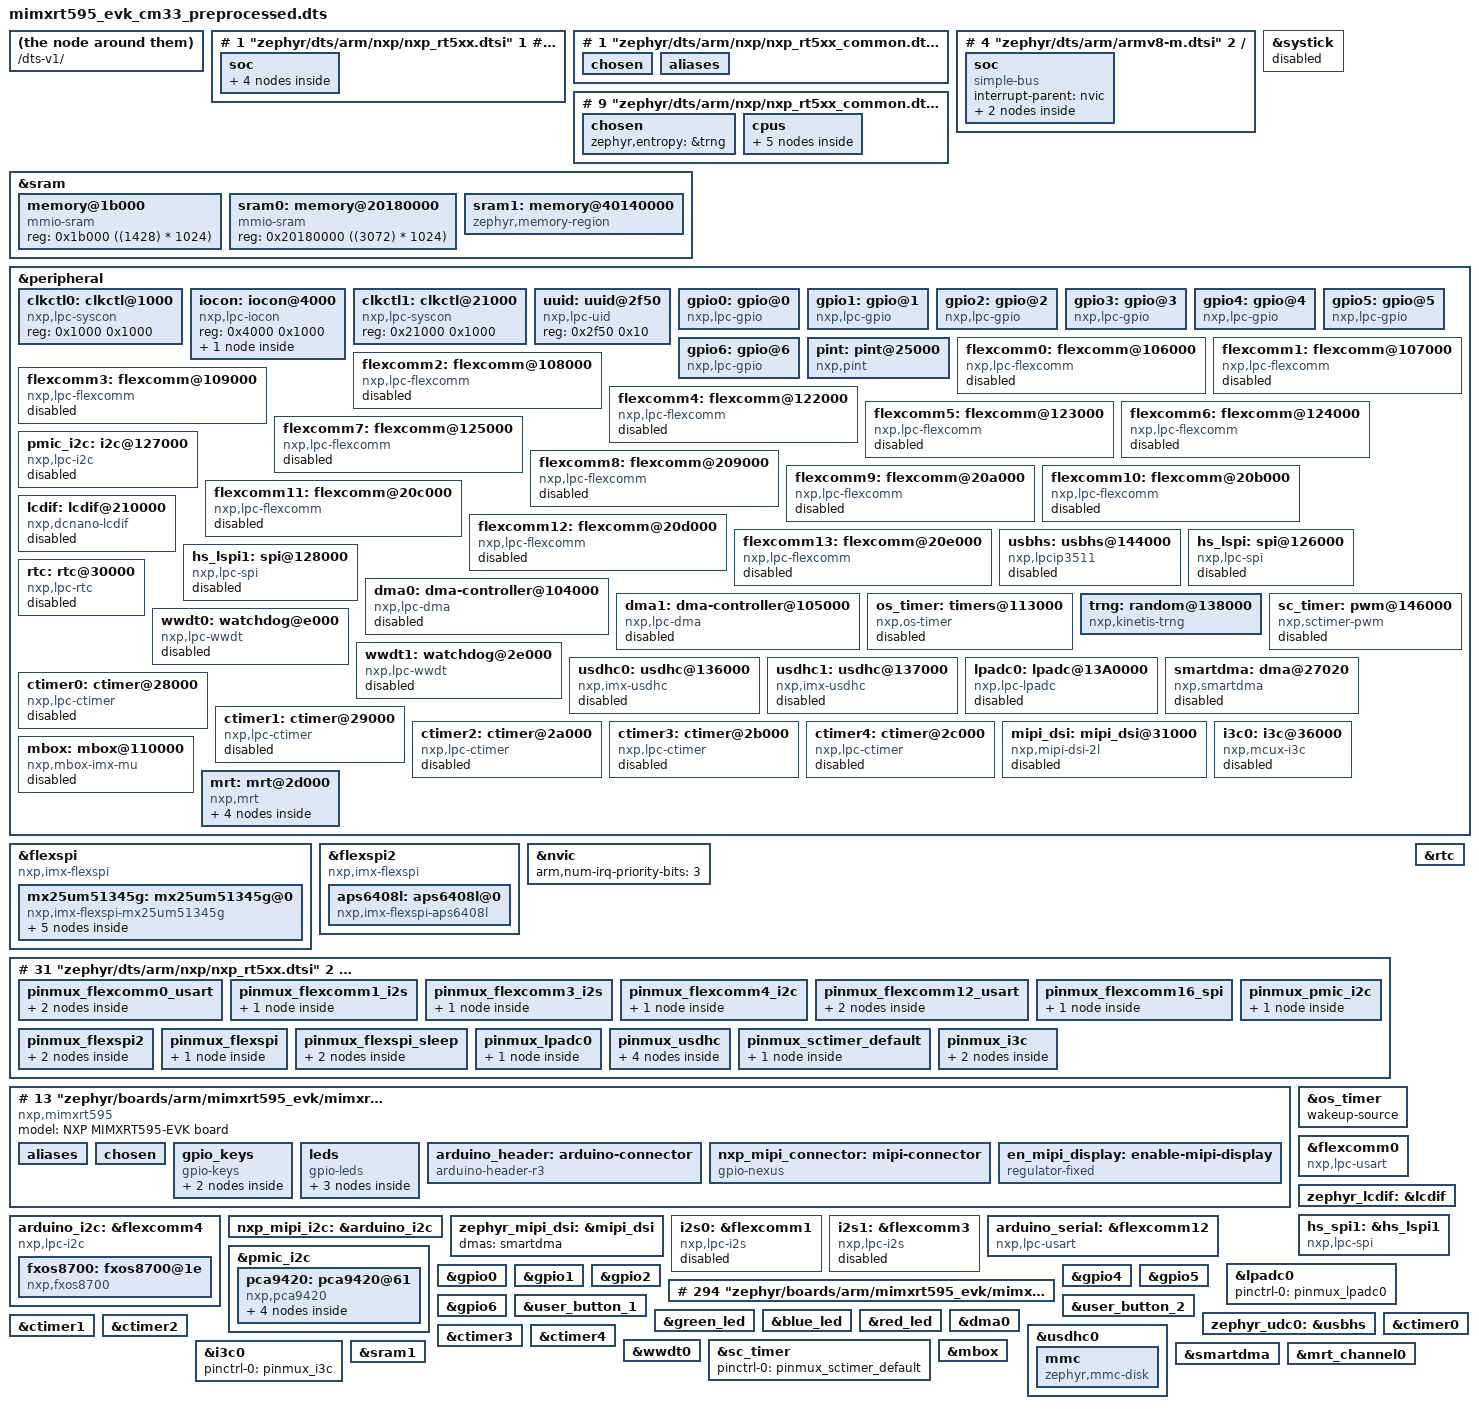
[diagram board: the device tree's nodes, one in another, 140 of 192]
# 0 "zephyr/boards/arm/mimxrt595_evk/mimxrt595_evk_cm33.dts"
# 0 "<built-in>"
# 0 "<command-line>"
# 1 "zephyr/boards/arm/mimxrt595_evk/mimxrt595_evk_cm33.dts"






/dts-v1/;

# 1 "zephyr/dts/arm/nxp/nxp_rt5xx.dtsi" 1






# 1 "zephyr/dts/common/mem.h" 1
# 8 "zephyr/dts/arm/nxp/nxp_rt5xx.dtsi" 2

/ {
 soc {
  sram: sram@30000000 {
   ranges = <0x0 0x10000000 0x500000
    0x20000000 0x30000000 0x500000>;
  };

  peripheral: peripheral@50000000 {
   ranges = <0x0 0x50000000 0x10000000>;
  };

  flexspi: spi@134000 {
   reg = <0x50134000 0x1000>, <0x18000000 ((128) * 1024 * 1024)>;
  };

  flexspi2: spi@13C000 {
   reg = <0x5013C000 0x1000>, <0x38000000 ((128) * 1024 * 1024)>;
  };
 };
};

# 1 "zephyr/dts/arm/nxp/nxp_rt5xx_common.dtsi" 1







# 1 "zephyr/dts/arm/armv8-m.dtsi" 1


# 1 "zephyr/dts/common/skeleton.dtsi" 1
# 9 "zephyr/dts/common/skeleton.dtsi"
/ {
 #address-cells = <1>;
 #size-cells = <1>;
 chosen { };
 aliases { };
};
# 4 "zephyr/dts/arm/armv8-m.dtsi" 2

/ {
 soc {
  #address-cells = <1>;
  #size-cells = <1>;
  compatible = "simple-bus";
  interrupt-parent = <&nvic>;
  ranges;

  nvic: interrupt-controller@e000e100 {
   #address-cells = <1>;
   compatible = "arm,v8m-nvic";
   reg = <0xe000e100 0xc00>;
   interrupt-controller;
   #interrupt-cells = <2>;
  };

  systick: timer@e000e010 {
   compatible = "arm,armv8m-systick";
   reg = <0xe000e010 0x10>;
  };
 };
};
# 9 "zephyr/dts/arm/nxp/nxp_rt5xx_common.dtsi" 2
# 1 "zephyr/include/zephyr/dt-bindings/adc/adc.h" 1
# 10 "zephyr/dts/arm/nxp/nxp_rt5xx_common.dtsi" 2
# 1 "zephyr/include/zephyr/dt-bindings/clock/mcux_lpc_syscon_clock.h" 1
# 11 "zephyr/dts/arm/nxp/nxp_rt5xx_common.dtsi" 2
# 1 "zephyr/include/zephyr/dt-bindings/gpio/gpio.h" 1
# 12 "zephyr/dts/arm/nxp/nxp_rt5xx_common.dtsi" 2
# 1 "zephyr/include/zephyr/dt-bindings/i2c/i2c.h" 1
# 13 "zephyr/dts/arm/nxp/nxp_rt5xx_common.dtsi" 2
# 1 "zephyr/include/zephyr/dt-bindings/mipi_dsi/mipi_dsi.h" 1
# 14 "zephyr/dts/arm/nxp/nxp_rt5xx_common.dtsi" 2
# 1 "zephyr/include/zephyr/dt-bindings/inputmux/inputmux_trigger_ports.h" 1
# 15 "zephyr/dts/arm/nxp/nxp_rt5xx_common.dtsi" 2
# 1 "zephyr/include/zephyr/dt-bindings/memory-attr/memory-attr-arm.h" 1
# 9 "zephyr/include/zephyr/dt-bindings/memory-attr/memory-attr-arm.h"
# 1 "zephyr/include/zephyr/sys/util_macro.h" 1
# 34 "zephyr/include/zephyr/sys/util_macro.h"
# 1 "zephyr/include/zephyr/sys/util_internal.h" 1
# 18 "zephyr/include/zephyr/sys/util_internal.h"
# 1 "zephyr/include/zephyr/sys/util_loops.h" 1
# 1083 "zephyr/include/zephyr/sys/util_loops.h"
# 1 "zephyr/include/zephyr/sys/util_listify.h" 1
# 1084 "zephyr/include/zephyr/sys/util_loops.h" 2
# 19 "zephyr/include/zephyr/sys/util_internal.h" 2
# 153 "zephyr/include/zephyr/sys/util_internal.h"
# 1 "zephyr/include/zephyr/sys/util_internal_is_eq.h" 1
# 154 "zephyr/include/zephyr/sys/util_internal.h" 2
# 184 "zephyr/include/zephyr/sys/util_internal.h"
# 1 "zephyr/include/zephyr/sys/util_internal_util_inc.h" 1
# 185 "zephyr/include/zephyr/sys/util_internal.h" 2


# 1 "zephyr/include/zephyr/sys/util_internal_util_dec.h" 1
# 188 "zephyr/include/zephyr/sys/util_internal.h" 2


# 1 "zephyr/include/zephyr/sys/util_internal_util_x2.h" 1
# 191 "zephyr/include/zephyr/sys/util_internal.h" 2
# 35 "zephyr/include/zephyr/sys/util_macro.h" 2
# 10 "zephyr/include/zephyr/dt-bindings/memory-attr/memory-attr-arm.h" 2
# 1 "zephyr/include/zephyr/dt-bindings/memory-attr/memory-attr.h" 1
# 11 "zephyr/include/zephyr/dt-bindings/memory-attr/memory-attr-arm.h" 2
# 16 "zephyr/dts/arm/nxp/nxp_rt5xx_common.dtsi" 2

/ {
 chosen {
  zephyr,entropy = &trng;
 };

 cpus {
  #address-cells = <1>;
  #size-cells = <0>;

  cpu0: cpu@0 {
   compatible = "arm,cortex-m33f";
   reg = <0>;
   #address-cells = <1>;
   #size-cells = <1>;
   cpu-power-states = <&idle &suspend>;

   mpu: mpu@e000ed90 {
    compatible = "arm,armv8m-mpu";
    reg = <0xe000ed90 0x40>;
   };
  };

  power-states {

   idle: idle {
    compatible = "zephyr,power-state";
    power-state-name = "runtime-idle";
    min-residency-us = <0>;
    exit-latency-us = <0>;
   };

   suspend: suspend {
    compatible = "nxp,pdcfg-power", "zephyr,power-state";
    power-state-name = "suspend-to-idle";
    min-residency-us = <500>;
    exit-latency-us = <120>;






    deep-sleep-config = <0xC800>,
       <0x80000004>,
       <0xFFFFFFFF>,
       <0>;
   };
  };
 };
};

&sram {
 #address-cells = <1>;
 #size-cells = <1>;
# 81 "zephyr/dts/arm/nxp/nxp_rt5xx_common.dtsi"
 sram_code: memory@1b000 {
  compatible = "mmio-sram";
  reg = <0x1b000 ((1428) * 1024)>;
 };

 sram0: memory@20180000 {
  compatible = "mmio-sram";
  reg = <0x20180000 ((3072) * 1024)>;
 };

 sram1: memory@40140000 {
  compatible = "zephyr,memory-region", "mmio-sram";
  reg = <0x40140000 ((16) * 1024)>;
  zephyr,memory-region = "SRAM1";
  zephyr,memory-attr = <( (((1UL << (0))) << (20)) )>;
 };
};

&systick {




 status = "disabled";
};

&peripheral {
 #address-cells = <1>;
 #size-cells = <1>;







 clkctl0: clkctl@1000 {
  compatible = "nxp,lpc-syscon";
  reg = <0x1000 0x1000>;
  #clock-cells = <1>;
 };

 iocon: iocon@4000 {
  compatible = "nxp,lpc-iocon";
  reg = <0x4000 0x1000>;
  pinctrl: pinctrl {
   compatible = "nxp,rt-iocon-pinctrl";
  };
 };

 clkctl1: clkctl@21000 {
  compatible = "nxp,lpc-syscon";
  reg = <0x21000 0x1000>;
  #clock-cells = <1>;
 };

 uuid: uuid@2f50 {
  compatible = "nxp,lpc-uid";
  reg = <0x2f50 0x10>;
 };

 gpio0: gpio@0 {
  compatible = "nxp,lpc-gpio";
  reg = <0x100000 0x1000>;
  int-source = "pint";
  gpio-controller;
  #gpio-cells = <2>;
  port = <0>;
 };

 gpio1: gpio@1 {
  compatible = "nxp,lpc-gpio";
  reg = <0x100000 0x1000>;
  int-source = "pint";
  gpio-controller;
  #gpio-cells = <2>;
  port = <1>;
 };

 gpio2: gpio@2 {
  compatible = "nxp,lpc-gpio";
  reg = <0x100000 0x1000>;
  gpio-controller;
  #gpio-cells = <2>;
  port = <2>;
 };

 gpio3: gpio@3 {
  compatible = "nxp,lpc-gpio";
  reg = <0x100000 0x1000>;
  gpio-controller;
  #gpio-cells = <2>;
  port = <3>;
 };

 gpio4: gpio@4 {
  compatible = "nxp,lpc-gpio";
  reg = <0x100000 0x1000>;
  gpio-controller;
  #gpio-cells = <2>;
  port = <4>;
 };

 gpio5: gpio@5 {
  compatible = "nxp,lpc-gpio";
  reg = <0x100000 0x1000>;
  gpio-controller;
  #gpio-cells = <2>;
  port = <5>;
 };

 gpio6: gpio@6 {
  compatible = "nxp,lpc-gpio";
  reg = <0x100000 0x1000>;
  gpio-controller;
  #gpio-cells = <2>;
  port = <6>;
 };

 pint: pint@25000 {
  compatible = "nxp,pint";
  reg = <0x25000 0x1000>;
  interrupt-controller;
  #interrupt-cells = <1>;
  #address-cells = <0>;
  interrupts = <4 2>, <5 2>, <6 2>, <7 2>,
   <35 2>, <36 2>, <37 2>, <38 2>;
  num-lines = <8>;
  num-inputs = <64>;
 };

 flexcomm0: flexcomm@106000 {
  compatible = "nxp,lpc-flexcomm";
  reg = <0x106000 0x1000>;
  interrupts = <14 0>;
  clocks = <&clkctl1 0>;
  status = "disabled";
 };

 flexcomm1: flexcomm@107000 {
  compatible = "nxp,lpc-flexcomm";
  reg = <0x107000 0x1000>;
  interrupts = <15 0>;
  clocks = <&clkctl1 1>;
  status = "disabled";
 };

 flexcomm2: flexcomm@108000 {
  compatible = "nxp,lpc-flexcomm";
  reg = <0x108000 0x1000>;
  interrupts = <16 0>;
  clocks = <&clkctl1 2>;
  status = "disabled";
 };

 flexcomm3: flexcomm@109000 {
  compatible = "nxp,lpc-flexcomm";
  reg = <0x109000 0x1000>;
  interrupts = <17 0>;
  clocks = <&clkctl1 3>;
  status = "disabled";
 };

 flexcomm4: flexcomm@122000 {
  compatible = "nxp,lpc-flexcomm";
  reg = <0x122000 0x1000>;
  interrupts = <18 0>;
  clocks = <&clkctl1 4>;
  status = "disabled";
 };

 flexcomm5: flexcomm@123000 {
  compatible = "nxp,lpc-flexcomm";
  reg = <0x123000 0x1000>;
  interrupts = <19 0>;
  clocks = <&clkctl1 5>;
  status = "disabled";
 };

 flexcomm6: flexcomm@124000 {
  compatible = "nxp,lpc-flexcomm";
  reg = <0x124000 0x1000>;
  interrupts = <43 0>;
  clocks = <&clkctl1 6>;
  status = "disabled";
 };

 flexcomm7: flexcomm@125000 {
  compatible = "nxp,lpc-flexcomm";
  reg = <0x125000 0x1000>;
  interrupts = <44 0>;
  clocks = <&clkctl1 7>;
  status = "disabled";
 };

 pmic_i2c: i2c@127000 {
  compatible = "nxp,lpc-i2c";
  reg = <0x127000 0x1000>;
  interrupts = <21 0>;
  clocks = <&clkctl1 15>;
  status = "disabled";
 };

 flexcomm8: flexcomm@209000 {
  compatible = "nxp,lpc-flexcomm";
  reg = <0x209000 0x1000>;
  interrupts = <60 0>;
  clocks = <&clkctl1 8>;
  status = "disabled";
 };

 flexcomm9: flexcomm@20a000 {
  compatible = "nxp,lpc-flexcomm";
  reg = <0x20a000 0x1000>;
  interrupts = <61 0>;
  clocks = <&clkctl1 9>;
  status = "disabled";
 };

 flexcomm10: flexcomm@20b000 {
  compatible = "nxp,lpc-flexcomm";
  reg = <0x20b000 0x1000>;
  interrupts = <62 0>;
  clocks = <&clkctl1 10>;
  status = "disabled";
 };

 flexcomm11: flexcomm@20c000 {
  compatible = "nxp,lpc-flexcomm";
  reg = <0x20c000 0x1000>;
  interrupts = <63 0>;
  clocks = <&clkctl1 11>;
  status = "disabled";
 };

 flexcomm12: flexcomm@20d000 {
  compatible = "nxp,lpc-flexcomm";
  reg = <0x20d000 0x1000>;
  interrupts = <64 0>;
  clocks = <&clkctl1 12>;
  status = "disabled";
 };

 flexcomm13: flexcomm@20e000 {
  compatible = "nxp,lpc-flexcomm";
  reg = <0x20e000 0x1000>;
  interrupts = <65 0>;
  clocks = <&clkctl1 13>;
  status = "disabled";
 };

 lcdif: lcdif@210000 {
  compatible = "nxp,dcnano-lcdif";
  reg = <0x210000 0x1000>;
  interrupts = <69 0>;
  status = "disabled";
 };

 usbhs: usbhs@144000 {
  compatible = "nxp,lpcip3511";
  reg = <0x144000 0x1000>;
  interrupts = <50 1>;
  num-bidir-endpoints = <6>;
  status = "disabled";
 };

 hs_lspi: spi@126000 {
  compatible = "nxp,lpc-spi";
  reg = <0x126000 0x1000>;
  interrupts = <20 0>;
  clocks = <&clkctl1 14>;
  status = "disabled";
  #address-cells = <1>;
  #size-cells = <0>;
 };

 hs_lspi1: spi@128000 {
  compatible = "nxp,lpc-spi";
  reg = <0x128000 0x1000>;
  interrupts = <66 0>;
  clocks = <&clkctl1 16>;
  status = "disabled";
  #address-cells = <1>;
  #size-cells = <0>;
 };

 dma0: dma-controller@104000 {
  compatible = "nxp,lpc-dma";
  reg = <0x104000 0x1000>;
  interrupts = <1 0>;
  dma-channels = <37>;
  nxp,dma-num-of-otrigs = <4>;
  nxp,dma-otrig-base-address = <0x30000000>;
  nxp,dma-itrig-base-address = <0x2000000E>;
  status = "disabled";
  #dma-cells = <1>;
 };

 dma1: dma-controller@105000 {
  compatible = "nxp,lpc-dma";
  reg = <0x105000 0x1000>;
  interrupts = <54 0>;
  dma-channels = <37>;
  nxp,dma-num-of-otrigs = <4>;
  nxp,dma-otrig-base-address = <0x50000000>;
  nxp,dma-itrig-base-address = <0x4000000E>;
  status = "disabled";
  #dma-cells = <1>;
 };

 os_timer: timers@113000 {
  compatible = "nxp,os-timer";
  reg = <0x113000 0x1000>;
  interrupts = <41 0>;
  status = "disabled";
 };

 rtc: rtc@30000 {
  compatible = "nxp,lpc-rtc";
  reg = <0x30000 0x1000>;
  interrupts = <32 0>;
  status = "disabled";
 };

 trng: random@138000 {
  compatible = "nxp,kinetis-trng";
  reg = <0x138000 0x1000>;
  status = "okay";
  interrupts = <31 0>;
 };

 sc_timer: pwm@146000 {
  compatible = "nxp,sctimer-pwm";
  reg = <0x146000 0x1000>;
  interrupts = <12 0>;
  status = "disabled";
  prescaler = <8>;
  #pwm-cells = <3>;
  clocks = <&clkctl1 34>;
 };

 wwdt0: watchdog@e000 {
  compatible = "nxp,lpc-wwdt";
  reg = <0xe000 0x1000>;
  interrupts = <0 0>;
  status = "disabled";
  clk-divider = <1>;
 };

 wwdt1: watchdog@2e000 {
  compatible = "nxp,lpc-wwdt";
  reg = <0x2e000 0x1000>;
  interrupts = <52 0>;
  status = "disabled";
  clk-divider = <1>;
 };

 usdhc0: usdhc@136000 {
  compatible = "nxp,imx-usdhc";
  reg = <0x136000 0x1000>;
  status = "disabled";
  interrupts = <45 0>;
  clocks = <&clkctl1 20>;
  max-current-330 = <1020>;
  max-current-180 = <1020>;
  max-bus-freq = <208000000>;
  min-bus-freq = <400000>;
 };

 usdhc1: usdhc@137000 {
  compatible = "nxp,imx-usdhc";
  reg = <0x137000 0x1000>;
  status = "disabled";
  interrupts = <46 0>;
  clocks = <&clkctl1 21>;
  max-current-330 = <1020>;
  max-current-180 = <1020>;
  max-bus-freq = <208000000>;
  min-bus-freq = <400000>;
 };

 lpadc0: lpadc@13A0000 {
  compatible = "nxp,lpc-lpadc";
  reg = <0x13A000 0x304>;
  interrupts = <22 0>;
  status = "disabled";
  clk-divider = <1>;
  clk-source = <0>;
  voltage-ref= <1>;
  calibration-average = <128>;
  power-level = <0>;
  offset-value-a = <10>;
  offset-value-b = <10>;
  #io-channel-cells = <1>;
 };

 smartdma: dma@27020 {
  compatible = "nxp,smartdma";
  reg = <0x27020 0x1000>;
  program-mem = <0x24100000>;
  interrupts = <73 0>;
  status = "disabled";
  #dma-cells = <0>;
 };

 ctimer0: ctimer@28000 {
  compatible = "nxp,lpc-ctimer";
  reg = <0x28000 0x1000>;
  interrupts = <10 0>;
  status = "disabled";
  clk-source = <1>;
  clocks = <&clkctl1 0>;
  mode = <0>;
  input = <0>;
  prescale = <0>;
 };

 ctimer1: ctimer@29000 {
  compatible = "nxp,lpc-ctimer";
  reg = <0x29000 0x1000>;
  interrupts = <11 0>;
  status = "disabled";
  clk-source = <1>;
  clocks = <&clkctl1 1>;
  mode = <0>;
  input = <0>;
  prescale = <0>;
 };

 ctimer2: ctimer@2a000 {
  compatible = "nxp,lpc-ctimer";
  reg = <0x2a000 0x1000>;
  interrupts = <39 0>;
  status = "disabled";
  clk-source = <1>;
  clocks = <&clkctl1 2>;
  mode = <0>;
  input = <0>;
  prescale = <0>;
 };

 ctimer3: ctimer@2b000 {
  compatible = "nxp,lpc-ctimer";
  reg = <0x2b000 0x1000>;
  interrupts = <13 0>;
  status = "disabled";
  clk-source = <1>;
  clocks = <&clkctl1 3>;
  mode = <0>;
  input = <0>;
  prescale = <0>;
 };

 ctimer4: ctimer@2c000 {
  compatible = "nxp,lpc-ctimer";
  reg = <0x2c000 0x1000>;
  interrupts = <40 0>;
  status = "disabled";
  clk-source = <1>;
  clocks = <&clkctl1 4>;
  mode = <0>;
  input = <0>;
  prescale = <0>;
 };

 mipi_dsi: mipi_dsi@31000 {
  compatible = "nxp,mipi-dsi-2l";
  #address-cells = <1>;
  #size-cells = <0>;
  reg = <0x31000 0x1000>;
  interrupts = <71 0>;
  clocks = <&clkctl1 31>,
   <&clkctl1 32>,
   <&clkctl1 33>;
  clock-names = "dphy", "esc", "pixel";
  status = "disabled";
 };

 i3c0: i3c@36000 {
  compatible = "nxp,mcux-i3c";
  reg = <0x36000 0x1000>;
  interrupts = <49 0>;
  clocks = <&clkctl1 30>;
  clk-divider = <2>;
  clk-divider-slow = <1>;
  clk-divider-tc = <1>;
  status = "disabled";
  #address-cells = <3>;
  #size-cells = <0>;
 };

 mbox:mbox@110000 {
  compatible = "nxp,mbox-imx-mu";
  reg = <0x110000 0x100>;
  interrupts = <34 0>;
  rx-channels = <4>;
  #mbox-cells = <1>;
  status = "disabled";
 };

 mrt: mrt@2d000 {
  compatible = "nxp,mrt";
  reg = <0x2d000 0x100>;
  interrupts = <9 0>;
  num-channels = <4>;
  num-bits = <24>;
  clocks = <&clkctl1 40>;
  #address-cells = <1>;
  #size-cells = <0>;

  mrt_channel0: mrt_channel@0 {
   compatible = "nxp,mrt-channel";
   reg = <0>;
   status = "disabled";
  };
  mrt_channel1: mrt_channel@1 {
   compatible = "nxp,mrt-channel";
   reg = <1>;
   status = "disabled";
  };
  mrt_channel2: mrt_channel@2 {
   compatible = "nxp,mrt-channel";
   reg = <2>;
   status = "disabled";
  };
  mrt_channel3: mrt_channel@3 {
   compatible = "nxp,mrt-channel";
   reg = <3>;
   status = "disabled";
  };
 };
};

&flexspi {
 compatible = "nxp,imx-flexspi";
 status = "disabled";
 interrupts = <42 0>;
 #address-cells = <1>;
 #size-cells = <0>;
};

&flexspi2 {
 compatible = "nxp,imx-flexspi";
 status = "disabled";
 interrupts = <42 0>;
 #address-cells = <1>;
 #size-cells = <0>;
};

&nvic {
 arm,num-irq-priority-bits = <3>;
};
# 31 "zephyr/dts/arm/nxp/nxp_rt5xx.dtsi" 2
# 10 "zephyr/boards/arm/mimxrt595_evk/mimxrt595_evk_cm33.dts" 2
# 1 "zephyr/include/zephyr/dt-bindings/input/input-event-codes.h" 1
# 11 "zephyr/boards/arm/mimxrt595_evk/mimxrt595_evk_cm33.dts" 2

# 1 "zephyr/boards/arm/mimxrt595_evk/mimxrt595_evk_cm33-pinctrl.dtsi" 1
# 10 "zephyr/boards/arm/mimxrt595_evk/mimxrt595_evk_cm33-pinctrl.dtsi"
# 1 "modules/hal/nxp/dts/nxp/nxp_imx/rt/MIMXRT595SFFOC-pinctrl.h" 1
# 11 "zephyr/boards/arm/mimxrt595_evk/mimxrt595_evk_cm33-pinctrl.dtsi" 2

&pinctrl {
 pinmux_flexcomm0_usart: pinmux_flexcomm0_usart {
  group0 {
   pinmux = <((((2) & 0xFFF) << 20) | (((1) & 0xF) << 0))>;
   input-enable;
   slew-rate = "normal";
   drive-strength = "normal";
  };
  group1 {
   pinmux = <((((1) & 0xFFF) << 20) | (((1) & 0xF) << 0))>;
   slew-rate = "normal";
   drive-strength = "normal";
  };
 };


 pinmux_flexcomm1_i2s: pinmux_flexcomm1_i2s {
  group0 {
   pinmux = <((((9) & 0xFFF) << 20) | (((1) & 0xF) << 0))>,
    <((((8) & 0xFFF) << 20) | (((1) & 0xF) << 0))>,
    <((((7) & 0xFFF) << 20) | (((1) & 0xF) << 0))>;
   slew-rate = "normal";
   input-enable;
   drive-strength = "high";
  };
 };


 pinmux_flexcomm3_i2s: pinmux_flexcomm3_i2s {
  group0 {
   pinmux = <((((23) & 0xFFF) << 20) | (((1) & 0xF) << 0))>;
   input-enable;
   slew-rate = "normal";
   drive-strength = "high";
  };
 };

 pinmux_flexcomm4_i2c: pinmux_flexcomm4_i2c {
  group0 {
   pinmux = <((((29) & 0xFFF) << 20) | (((1) & 0xF) << 0))>,
          <((((30) & 0xFFF) << 20) | (((1) & 0xF) << 0))>;
   input-enable;
   slew-rate = "normal";
   drive-strength = "high";
   drive-open-drain;
  };
 };

 pinmux_flexcomm12_usart: pinmux_flexcomm12_usart {
  group0 {
   pinmux = <((((159) & 0xFFF) << 20) | (((6) & 0xF) << 0))>;
   input-enable;
   slew-rate = "normal";
   drive-strength = "normal";
  };
  group1 {
   pinmux = <((((158) & 0xFFF) << 20) | (((6) & 0xF) << 0))>;
   slew-rate = "normal";
   drive-strength = "normal";
  };
 };

 pinmux_flexcomm16_spi: pinmux_flexcomm16_spi {
  group0 {
   pinmux = <((((35) & 0xFFF) << 20) | (((6) & 0xF) << 0))>,
     <((((36) & 0xFFF) << 20) | (((6) & 0xF) << 0))>,
     <((((37) & 0xFFF) << 20) | (((6) & 0xF) << 0))>,
     <((((38) & 0xFFF) << 20) | (((6) & 0xF) << 0))>;
   input-enable;
   slew-rate = "normal";
   drive-strength = "normal";
  };
 };

 pinmux_pmic_i2c: pinmux_pmic_i2c {
  group0 {
   pinmux = <((((256) & 0xFFF) << 20) | (((0) & 0xF) << 0))>,
    <((((257) & 0xFFF) << 20) | (((0) & 0xF) << 0))>;
   bias-pull-up;
   input-enable;
   slew-rate = "normal";
   drive-strength = "normal";
   drive-open-drain;
  };
 };

 pinmux_flexspi2: pinmux_flexspi2 {
  group0 {
   pinmux =
    <((((139) & 0xFFF) << 20) | (((2) & 0xF) << 0))>,
    <((((140) & 0xFFF) << 20) | (((2) & 0xF) << 0))>,
    <((((141) & 0xFFF) << 20) | (((2) & 0xF) << 0))>,
    <((((142) & 0xFFF) << 20) | (((2) & 0xF) << 0))>,
    <((((143) & 0xFFF) << 20) | (((2) & 0xF) << 0))>,
    <((((175) & 0xFFF) << 20) | (((2) & 0xF) << 0))>,
    <((((176) & 0xFFF) << 20) | (((2) & 0xF) << 0))>,
    <((((177) & 0xFFF) << 20) | (((2) & 0xF) << 0))>,
    <((((178) & 0xFFF) << 20) | (((2) & 0xF) << 0))>,
    <((((146) & 0xFFF) << 20) | (((2) & 0xF) << 0))>;
   slew-rate = "normal";
   input-enable;
   drive-strength = "high";
  };
  group1 {
   pinmux = <((((144) & 0xFFF) << 20) | (((2) & 0xF) << 0))>;
   slew-rate = "normal";
   input-enable;
   drive-strength = "high";
   bias-pull-down;
  };
 };

 pinmux_flexspi: pinmux_flexspi {
  group0 {
   pinmux = <((((50) & 0xFFF) << 20) | (((1) & 0xF) << 0))>,
     <((((51) & 0xFFF) << 20) | (((1) & 0xF) << 0))>,
     <((((52) & 0xFFF) << 20) | (((1) & 0xF) << 0))>,
     <((((53) & 0xFFF) << 20) | (((1) & 0xF) << 0))>,
     <((((54) & 0xFFF) << 20) | (((1) & 0xF) << 0))>,
     <((((55) & 0xFFF) << 20) | (((1) & 0xF) << 0))>,
     <((((56) & 0xFFF) << 20) | (((1) & 0xF) << 0))>,
     <((((57) & 0xFFF) << 20) | (((1) & 0xF) << 0))>,
     <((((58) & 0xFFF) << 20) | (((1) & 0xF) << 0))>,
     <((((59) & 0xFFF) << 20) | (((1) & 0xF) << 0))>;
   input-enable;
   slew-rate = "normal";
   drive-strength = "high";
  };
 };

 pinmux_flexspi_sleep: pinmux_flexspi_sleep {
  group0 {
   pinmux = <((((50) & 0xFFF) << 20) | (((1) & 0xF) << 0))>,
     <((((51) & 0xFFF) << 20) | (((1) & 0xF) << 0))>;
   slew-rate = "normal";
   drive-strength = "high";
  };
  group1 {
   pinmux = <((((52) & 0xFFF) << 20) | (((1) & 0xF) << 0))>,
     <((((53) & 0xFFF) << 20) | (((1) & 0xF) << 0))>,
     <((((54) & 0xFFF) << 20) | (((1) & 0xF) << 0))>,
     <((((55) & 0xFFF) << 20) | (((1) & 0xF) << 0))>,
     <((((56) & 0xFFF) << 20) | (((1) & 0xF) << 0))>,
     <((((57) & 0xFFF) << 20) | (((1) & 0xF) << 0))>,
     <((((58) & 0xFFF) << 20) | (((1) & 0xF) << 0))>,
     <((((59) & 0xFFF) << 20) | (((1) & 0xF) << 0))>;
   input-enable;
   slew-rate = "normal";
   drive-strength = "high";
   bias-pull-up;
  };
 };

 pinmux_lpadc0: pinmux_lpadc0 {
  group0 {
   pinmux = <((((5) & 0xFFF) << 20) | (((0) & 0xF) << 0))>,
    <((((6) & 0xFFF) << 20) | (((0) & 0xF) << 0))>,
    <((((19) & 0xFFF) << 20) | (((0) & 0xF) << 0))>;
   slew-rate = "normal";
   drive-strength = "normal";
   nxp,analog-mode;
  };
 };

 pinmux_usdhc: pinmux_usdhc {
  group0 {
   pinmux = <((((63) & 0xFFF) << 20) | (((1) & 0xF) << 0))>,
     <((((64) & 0xFFF) << 20) | (((1) & 0xF) << 0))>,
     <((((65) & 0xFFF) << 20) | (((1) & 0xF) << 0))>,
     <((((66) & 0xFFF) << 20) | (((1) & 0xF) << 0))>,
     <((((67) & 0xFFF) << 20) | (((1) & 0xF) << 0))>,
     <((((69) & 0xFFF) << 20) | (((1) & 0xF) << 0))>,
     <((((70) & 0xFFF) << 20) | (((1) & 0xF) << 0))>,
     <((((71) & 0xFFF) << 20) | (((1) & 0xF) << 0))>,
     <((((72) & 0xFFF) << 20) | (((1) & 0xF) << 0))>,
     <((((73) & 0xFFF) << 20) | (((1) & 0xF) << 0))>;
   bias-pull-up;
   input-enable;
   slew-rate = "normal";
   drive-strength = "normal";
  };
  group1 {
   pinmux = <((((62) & 0xFFF) << 20) | (((1) & 0xF) << 0))>;
   bias-pull-down;
   input-enable;
   slew-rate = "normal";
   drive-strength = "normal";
  };
  group2 {
   pinmux = <((((74) & 0xFFF) << 20) | (((0) & 0xF) << 0))>;
   bias-pull-down;
   slew-rate = "normal";
   drive-strength = "normal";
  };
  group3 {
   pinmux = <((((68) & 0xFFF) << 20) | (((5) & 0xF) << 0))>;
   bias-pull-down;
   input-enable;
   slew-rate = "slow";
   drive-strength = "normal";
  };
 };

 pinmux_sctimer_default: pinmux_sctimer_default {
  group0 {
   pinmux = <((((5) & 0xFFF) << 20) | (((3) & 0xF) << 0))>,
          <((((6) & 0xFFF) << 20) | (((3) & 0xF) << 0))>;
   slew-rate = "normal";
   drive-strength = "normal";
  };
 };

 pinmux_i3c: pinmux_i3c {
  group0 {
   pinmux = <((((93) & 0xFFF) << 20) | (((1) & 0xF) << 0))>,
    <((((94) & 0xFFF) << 20) | (((1) & 0xF) << 0))>;
   input-enable;
   slew-rate = "slow";
   drive-strength = "high";
  };

  group1 {
   pinmux = <((((95) & 0xFFF) << 20) | (((1) & 0xF) << 0))>;
   slew-rate = "normal";
   drive-strength = "normal";
  };
 };

};
# 13 "zephyr/boards/arm/mimxrt595_evk/mimxrt595_evk_cm33.dts" 2


/ {
 model = "NXP MIMXRT595-EVK board";
 compatible = "nxp,mimxrt595";

 aliases {
  sw0 = &user_button_1;
  sw1 = &user_button_2;
  led0 = &green_led;
  led1 = &blue_led;
  led2 = &red_led;
  usart-0 = &flexcomm0;
  watchdog0 = &wwdt0;
  magn0 = &fxos8700;
  accel0 = &fxos8700;
  sdhc0 = &usdhc0;
  pwm-0 = &sc_timer;
 };

 chosen {
  zephyr,flash-controller = &mx25um51345g;
  zephyr,flash = &mx25um51345g;
  zephyr,code-partition = &slot0_partition;
  zephyr,sram = &sram0;
  zephyr,console = &flexcomm0;
  zephyr,shell-uart = &flexcomm0;
  zephyr,display = &lcdif;
 };

 gpio_keys {
  compatible = "gpio-keys";
  user_button_1: button_0 {
   label = "User SW1";
   gpios = <&gpio0 25 (1 << 0)>;
   zephyr,code = <11>;
  };
  user_button_2: button_1 {
   label = "User SW2";
   gpios = <&gpio0 10 (1 << 0)>;
   zephyr,code = <2>;
  };
 };

 leds {
  compatible = "gpio-leds";
  green_led: led_1 {
   gpios = <&gpio1 0 0>;
   label = "User LED_GREEN";
  };
  blue_led: led_2 {
   gpios = <&gpio3 17 0>;
   label = "User LED_BLUE";
  };
  red_led: led_3 {
   gpios = <&gpio0 14 0>;
   label = "User LED_RED";
  };
 };

 arduino_header: arduino-connector {
  compatible = "arduino-header-r3";
  #gpio-cells = <2>;
  gpio-map-mask = <0xffffffff 0xffffffc0>;
  gpio-map-pass-thru = <0 0x3f>;
  gpio-map = <0 0 &gpio0 5 0>,
    <1 0 &gpio0 6 0>,
    <2 0 &gpio0 19 0>,
    <3 0 &gpio0 13 0>,
    <4 0 &gpio4 22 0>,
    <5 0 &gpio4 21 0>,
    <6 0 &gpio4 31 0>,
    <7 0 &gpio4 30 0>,
    <8 0 &gpio4 20 0>,
    <9 0 &gpio4 23 0>,
    <10 0 &gpio4 24 0>,
    <11 0 &gpio4 25 0>,
    <12 0 &gpio4 26 0>,
    <13 0 &gpio4 27 0>,
    <14 0 &gpio4 28 0>,
    <15 0 &gpio4 29 0>,
    <16 0 &gpio5 0 0>,
    <17 0 &gpio5 1 0>,
    <18 0 &gpio5 2 0>,
    <19 0 &gpio5 3 0>,
    <20 0 &gpio4 22 0>,
    <21 0 &gpio4 21 0>;
 };







 nxp_mipi_connector: mipi-connector {
  compatible = "gpio-nexus";
  #gpio-cells = <2>;
  gpio-map-mask = <0xffffffff 0xffffffc0>;
  gpio-map-pass-thru = <0 0x3f>;
  gpio-map = <0 0 &gpio0 12 0>,
    <21 0 &gpio3 21 0>,
    <22 0 &gpio3 18 0>,
    <26 0 &gpio0 30 0>,
    <27 0 &gpio0 29 0>,
    <28 0 &gpio4 4 0>,
    <29 0 &gpio3 19 0>,
    <32 0 &gpio3 15 0>,
    <34 0 &gpio0 12 0>;
 };

 en_mipi_display: enable-mipi-display {
  compatible = "regulator-fixed";
  regulator-name = "en_mipi_display";
  enable-gpios = <&gpio3 15 (0 << 0)>;
  regulator-boot-on;
 };
};






&os_timer {
 status = "okay";
 wakeup-source;
};

&rtc {
 status = "okay";
};

&flexcomm0 {
 compatible = "nxp,lpc-usart";
 status = "okay";
 current-speed = <115200>;
 pinctrl-0 = <&pinmux_flexcomm0_usart>;
 pinctrl-names = "default";
 dmas = <&dma0 0>, <&dma0 1>;
 dma-names = "rx", "tx";
};

arduino_i2c: &flexcomm4 {
 compatible = "nxp,lpc-i2c";
 status = "okay";
 clock-frequency = <400000>;
 #address-cells = <1>;
 #size-cells = <0>;
 pinctrl-0 = <&pinmux_flexcomm4_i2c>;
 pinctrl-names = "default";

 fxos8700: fxos8700@1e {
  compatible = "nxp,fxos8700";
  reg = <0x1e>;
  int1-gpios = <&gpio0 22 (1 << 0)>;
  reset-gpios = <&gpio1 7 (0 << 0)>;
 };
};

nxp_mipi_i2c: &arduino_i2c {};

zephyr_mipi_dsi: &mipi_dsi {};

zephyr_lcdif: &lcdif {};


hs_spi1: &hs_lspi1 {
 compatible = "nxp,lpc-spi";
 pinctrl-0 = <&pinmux_flexcomm16_spi>;
 pinctrl-names = "default";
 dmas = <&dma0 28>, <&dma0 29>;
 dma-names = "rx", "tx";
 status = "okay";
};


i2s0: &flexcomm1 {
 compatible = "nxp,lpc-i2s";
 pinctrl-0 = <&pinmux_flexcomm1_i2s>;
 pinctrl-names = "default";
 #address-cells = <1>;
 #size-cells = <0>;
 dmas = <&dma0 2>;
 dma-names = "rx";
 status = "disabled";
};


i2s1: &flexcomm3 {
 compatible = "nxp,lpc-i2s";
 pinctrl-0 = <&pinmux_flexcomm3_i2s>;
 pinctrl-names = "default";
 #address-cells = <1>;
 #size-cells = <0>;
 dmas = <&dma0 7>;
 dma-names = "tx";
 status = "disabled";
};

arduino_serial: &flexcomm12 {
 compatible = "nxp,lpc-usart";
 status = "okay";
 current-speed = <115200>;
 pinctrl-0 = <&pinmux_flexcomm12_usart>;
 pinctrl-names = "default";
 dmas = <&dma0 34>, <&dma0 35>;
 dma-names = "rx", "tx";
};


&pmic_i2c {
 status = "okay";
 clock-frequency = <400000>;
 #address-cells = <1>;
 #size-cells = <0>;
 pinctrl-0 = <&pinmux_pmic_i2c>;
 pinctrl-names = "default";

 pca9420: pca9420@61 {
  compatible = "nxp,pca9420";
  reg = <0x61>;
  nxp,enable-modesel-pins;

  pca9420_sw1: BUCK1 {
   regulator-boot-on;
   nxp,mode0-microvolt = <1100000>;
   nxp,mode1-microvolt = <600000>;
   nxp,mode2-microvolt = <0>;
  };

  pca9420_sw2: BUCK2 {
   regulator-boot-on;
   nxp,mode0-microvolt = <1800000>;
   nxp,mode1-microvolt = <1800000>;
   nxp,mode2-microvolt = <1800000>;

  };

  pca9420_ldo1: LDO1 {
   regulator-boot-on;
   nxp,mode0-microvolt = <1800000>;
   nxp,mode1-microvolt = <1800000>;
   nxp,mode2-microvolt = <1800000>;
  };

  pca9420_ldo2: LDO2 {
   regulator-boot-on;
   nxp,mode0-microvolt = <3300000>;
   nxp,mode1-microvolt = <3300000>;
   nxp,mode2-microvolt = <3300000>;
  };
 };
};

&lpadc0 {
 status = "okay";
 pinctrl-0 = <&pinmux_lpadc0>;
 pinctrl-names = "default";
};

&gpio0 {
 status = "okay";
};

&gpio1 {
 status = "okay";
};

&gpio2 {
 status = "okay";
};
# 294 "zephyr/boards/arm/mimxrt595_evk/mimxrt595_evk_cm33.dts"
&gpio3 {
 status = "okay";
 int-source = "int-a";
 interrupts = <2 0>;
};

&gpio4 {
 status = "okay";
 int-source = "int-b";
 interrupts = <3 0>;
};

&gpio5 {
 status = "okay";
};

&gpio6 {
 status = "okay";
};

&user_button_1 {
 status = "okay";
};

&user_button_2 {
 status = "okay";
};

&green_led {
 status = "okay";
};

&blue_led {
 status = "okay";
};

&red_led {
 status = "okay";
};

&dma0 {
 status = "okay";
};

zephyr_udc0: &usbhs {
 status = "okay";
};

&ctimer0 {
 status = "okay";
};

&ctimer1 {
 status = "okay";
};

&ctimer2 {
 status = "okay";
};

&ctimer3 {
 status = "okay";
};

&ctimer4 {
 status = "okay";
};

&usdhc0 {
 status = "okay";
 pwr-gpios = <&gpio2 10 (0 << 0)>;
 cd-gpios = <&gpio2 9 (1 << 0)>;
 mmc {
  compatible = "zephyr,mmc-disk";
  status = "okay";
 };
 pinctrl-0 = <&pinmux_usdhc>;
 pinctrl-names = "default";
 mmc-hs200-1_8v;
 mmc-hs400-1_8v;
};

&wwdt0 {
 status = "okay";
};

&flexspi {
 status = "okay";
 pinctrl-0 = <&pinmux_flexspi>;
 pinctrl-1 = <&pinmux_flexspi_sleep>;
 pinctrl-names = "default", "sleep";

 mx25um51345g: mx25um51345g@0 {
  compatible = "nxp,imx-flexspi-mx25um51345g";

  size = <((64 * 8) * 1024 * 1024)>;
  reg = <0>;
  spi-max-frequency = <200000000>;
  status = "okay";
  jedec-id = [c2 81 3a];
  erase-block-size = <4096>;
  write-block-size = <16>;

  partitions {
   compatible = "fixed-partitions";
   #address-cells = <1>;
   #size-cells = <1>;

   boot_partition: partition@0 {
    label = "mcuboot";
    reg = <0x00000000 ((128) * 1024)>;
   };
   slot0_partition: partition@20000 {
    label = "image-0";
    reg = <0x00020000 ((3076) * 1024)>;
   };
   slot1_partition: partition@321000 {
    label = "image-1";
    reg = <0x00321000 ((3072) * 1024)>;
   };
   storage_partition: partition@621000 {
    label = "storage";
    reg = <0x00621000 ((57) * 1024 * 1024)>;
   };
  };
 };
};

&flexspi2 {
 status = "okay";
 pinctrl-0 = <&pinmux_flexspi2>;
 pinctrl-names = "default";
 rx-clock-source = <3>;
 ahb-prefetch;
 ahb-bufferable;
 ahb-cacheable;
 ahb-read-addr-opt;
 aps6408l: aps6408l@0 {
  compatible = "nxp,imx-flexspi-aps6408l";

  size = <((8 * 8) * 1024 * 1024)>;
  reg = <0>;
  spi-max-frequency = <198000000>;
  status = "okay";
  cs-interval-unit = <1>;
  cs-interval = <5>;
  cs-hold-time = <3>;
  cs-setup-time = <3>;
  data-valid-time = <1>;
  column-space = <0>;
  ahb-write-wait-unit = <2>;
  ahb-write-wait-interval = <0>;
 };
};

&sc_timer {
 pinctrl-0 = <&pinmux_sctimer_default>;
 pinctrl-names = "default";
 status = "okay";
};

&i3c0 {
 pinctrl-0 = <&pinmux_i3c>;
 pinctrl-names = "default";

 status = "okay";
};

&mbox {
 status = "okay";
};


&sram1 {
 status = "okay";
};


&smartdma {
 status = "okay";
};


&mipi_dsi {
 dmas = <&smartdma>;
 dma-names = "smartdma";
};

&mrt_channel0 {
 status = "okay";
};
